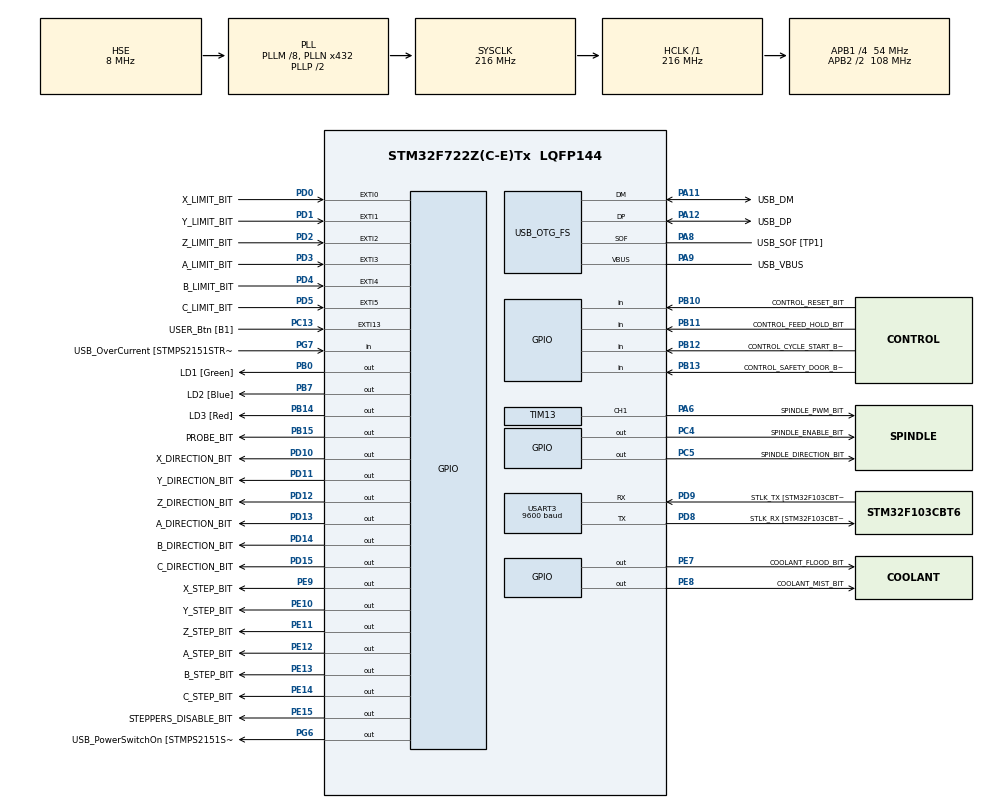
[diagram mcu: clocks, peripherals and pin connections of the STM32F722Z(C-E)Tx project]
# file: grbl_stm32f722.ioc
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Mcu.Family=STM32F7
Mcu.Name=STM32F722Z(C-E)Tx
Mcu.Package=LQFP144
NVIC.EXTI0_IRQn=true\:0\:0\:false\:false\:true\:true\:true
NVIC.EXTI15_10_IRQn=true\:0\:0\:false\:false\:true\:true\:true
NVIC.EXTI1_IRQn=true\:0\:0\:false\:false\:true\:true\:true
NVIC.EXTI2_IRQn=true\:0\:0\:false\:false\:true\:true\:true
NVIC.EXTI3_IRQn=true\:0\:0\:false\:false\:true\:true\:true
NVIC.EXTI4_IRQn=true\:0\:0\:false\:false\:true\:true\:true
NVIC.EXTI9_5_IRQn=true\:0\:0\:false\:false\:true\:true\:true
NVIC.PriorityGroup=NVIC_PRIORITYGROUP_4
NVIC.TIM6_DAC_IRQn=true\:0\:0\:false\:false\:true\:true\:true
NVIC.TIM7_IRQn=true\:0\:0\:false\:false\:true\:true\:true
NVIC.USART3_IRQn=true\:0\:0\:false\:false\:true\:true\:true
PA10.GPIO_Label=USB_ID
PA10.Signal=USB_OTG_FS_ID
PA11.GPIO_Label=USB_DM
PA11.Mode=Device_Only
PA11.Signal=USB_OTG_FS_DM
PA12.GPIO_Label=USB_DP
PA12.Mode=Device_Only
PA12.Signal=USB_OTG_FS_DP
PA13.GPIO_Label=TMS
PA13.Mode=Serial_Wire
PA13.Signal=SYS_JTMS-SWDIO
PA14.GPIO_Label=TCK
PA14.Mode=Serial_Wire
PA14.Signal=SYS_JTCK-SWCLK
PA6.GPIO_Label=SPINDLE_PWM_BIT
PA6.Signal=S_TIM13_CH1
PA8.GPIO_Label=USB_SOF [TP1]
PA8.Mode=Activate_SOF_FS
PA8.Signal=USB_OTG_FS_SOF
PA9.GPIO_Label=USB_VBUS
PA9.Mode=Activate_VBUS
PA9.Signal=USB_OTG_FS_VBUS
PB0.GPIO_Label=LD1 [Green]
PB0.Signal=GPIO_Output
PB10.GPIO_Label=CONTROL_RESET_BIT
PB10.GPIO_PuPd=GPIO_PULLUP
PB10.Signal=GPIO_Input
PB11.GPIO_Label=CONTROL_FEED_HOLD_BIT
PB11.GPIO_PuPd=GPIO_PULLUP
PB11.Signal=GPIO_Input
PB12.GPIO_Label=CONTROL_CYCLE_START_BIT
PB12.GPIO_PuPd=GPIO_PULLUP
PB12.Signal=GPIO_Input
PB13.GPIO_Label=CONTROL_SAFETY_DOOR_BIT
PB13.GPIO_PuPd=GPIO_PULLUP
PB13.Signal=GPIO_Input
PB14.GPIO_Label=LD3 [Red]
PB14.Signal=GPIO_Output
PB15.GPIO_Label=PROBE_BIT
PB15.Signal=GPIO_Output
PB3.GPIO_Label=SWO
PB3.Signal=SYS_JTDO-SWO
PB7.GPIO_Label=LD2 [Blue]
PB7.Signal=GPIO_Output
PC13.GPIO_Label=USER_Btn [B1]
PC13.Signal=GPXTI13
PC14-OSC32_IN.Mode=LSE-External-Oscillator
PC14-OSC32_IN.Signal=RCC_OSC32_IN
PC15-OSC32_OUT.Mode=LSE-External-Oscillator
PC15-OSC32_OUT.Signal=RCC_OSC32_OUT
PC4.GPIO_Label=SPINDLE_ENABLE_BIT
PC4.Signal=GPIO_Output
PC5.GPIO_Label=SPINDLE_DIRECTION_BIT
PC5.Signal=GPIO_Output
PD0.GPIO_Label=X_LIMIT_BIT
PD0.GPIO_PuPd=GPIO_PULLUP
PD0.Signal=GPXTI0
PD1.GPIO_Label=Y_LIMIT_BIT
PD1.GPIO_PuPd=GPIO_PULLUP
PD1.Signal=GPXTI1
PD10.GPIO_Label=X_DIRECTION_BIT
PD10.Signal=GPIO_Output
PD11.GPIO_Label=Y_DIRECTION_BIT
PD11.Signal=GPIO_Output
PD12.GPIO_Label=Z_DIRECTION_BIT
PD12.Signal=GPIO_Output
PD13.GPIO_Label=A_DIRECTION_BIT
PD13.Signal=GPIO_Output
PD14.GPIO_Label=B_DIRECTION_BIT
PD14.Signal=GPIO_Output
PD15.GPIO_Label=C_DIRECTION_BIT
PD15.Signal=GPIO_Output
PD2.GPIO_Label=Z_LIMIT_BIT
PD2.GPIO_PuPd=GPIO_PULLUP
PD2.Signal=GPXTI2
PD3.GPIO_Label=A_LIMIT_BIT
PD3.GPIO_PuPd=GPIO_PULLUP
PD3.Signal=GPXTI3
PD4.GPIO_Label=B_LIMIT_BIT
PD4.GPIO_PuPd=GPIO_PULLUP
PD4.Signal=GPXTI4
PD5.GPIO_Label=C_LIMIT_BIT
PD5.GPIO_PuPd=GPIO_PULLUP
PD5.Signal=GPXTI5
PD8.GPIO_Label=STLK_RX [STM32F103CBT6_PA3]
PD8.Mode=Asynchronous
PD8.Signal=USART3_TX
PD9.GPIO_Label=STLK_TX [STM32F103CBT6_PA2]
PD9.Mode=Asynchronous
PD9.Signal=USART3_RX
PE10.GPIO_Label=Y_STEP_BIT
PE10.Signal=GPIO_Output
PE11.GPIO_Label=Z_STEP_BIT
PE11.Signal=GPIO_Output
PE12.GPIO_Label=A_STEP_BIT
PE12.Signal=GPIO_Output
PE13.GPIO_Label=B_STEP_BIT
PE13.Signal=GPIO_Output
PE14.GPIO_Label=C_STEP_BIT
PE14.Signal=GPIO_Output
PE15.GPIO_Label=STEPPERS_DISABLE_BIT
PE15.Signal=GPIO_Output
PE7.GPIO_Label=COOLANT_FLOOD_BIT
PE7.Signal=GPIO_Output
PE8.GPIO_Label=COOLANT_MIST_BIT
PE8.Signal=GPIO_Output
PE9.GPIO_Label=X_STEP_BIT
PE9.Signal=GPIO_Output
PG6.GPIO_Label=USB_PowerSwitchOn [STMPS2151STR_EN]
PG6.Signal=GPIO_Output
PG7.GPIO_Label=USB_OverCurrent [STMPS2151STR_FAULT]
PG7.Signal=GPIO_Input
PH0-OSC_IN.GPIO_Label=MCO
PH0-OSC_IN.Mode=HSE-External-Clock-Source
PH0-OSC_IN.Signal=RCC_OSC_IN
PH1-OSC_OUT.Mode=HSE-External-Clock-Source
PH1-OSC_OUT.Signal=RCC_OSC_OUT
ProjectManager.HeapSize=0x200
ProjectManager.StackSize=0x400
ProjectManager.TargetToolchain=STM32CubeIDE
RCC.48MHZClocksFreq_Value=24000000
RCC.AHBFreq_Value=216000000
RCC.APB1CLKDivider=RCC_HCLK_DIV4
RCC.APB1Freq_Value=54000000
RCC.APB1TimFreq_Value=108000000
RCC.APB2CLKDivider=RCC_HCLK_DIV2
RCC.APB2Freq_Value=108000000
RCC.APB2TimFreq_Value=216000000
RCC.CortexFreq_Value=216000000
RCC.HCLKFreq_Value=216000000
RCC.HSE_VALUE=8000000
RCC.HSI_VALUE=16000000
RCC.PLLM=8
RCC.PLLMUL=RCC_PLL_MUL9
RCC.PLLN=432
RCC.PLLQ=9
RCC.PRESCALERUSB=RCC_USBCLKSOURCE_PLL_DIV1_5
RCC.SYSCLKFreq_VALUE=216000000
RCC.SYSCLKSource=RCC_SYSCLKSOURCE_PLLCLK
RCC.SYSCLKSourceVirtual=RCC_SYSCLKSOURCE_PLLCLK
RCC.USBFreq_Value=48000000
RCC.VCOOutputFreq_Value=432000000
SH.S_TIM13_CH1.0=TIM13_CH1,PWM Generation1 CH1
TIM13.Channel=TIM_CHANNEL_1
TIM6.Prescaler=216
TIM7.Prescaler=216
USART3.BaudRate=9600
USART3.VirtualMode-Asynchronous=VM_ASYNC
USB_OTG_FS.VirtualMode=Device_Only
VP_TIM13_VS_ClockSourceINT.Mode=Enable_Timer
VP_TIM6_VS_ClockSourceINT.Mode=Enable_Timer
VP_TIM7_VS_ClockSourceINT.Mode=Enable_Timer
board=NUCLEO-F722ZE

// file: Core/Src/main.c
/* USER CODE BEGIN Header */
/**
  ******************************************************************************
  * @file           : main.c
  * @brief          : Main program body
  ******************************************************************************
  * @attention
  *
  * <h2><center>&copy; Copyright (c) 2020 STMicroelectronics.
  * All rights reserved.</center></h2>
  *
  * This software component is licensed by ST under BSD 3-Clause license,
  * the "License"; You may not use this file except in compliance with the
  * License. You may obtain a copy of the License at:
  *                        opensource.org/licenses/BSD-3-Clause
  *
  ******************************************************************************
  */
/* USER CODE END Header */

#include "main.h"

/* USER CODE BEGIN Includes */
#include "stm32_hal_port.h"

/* USER CODE END Includes */

TIM_HandleTypeDef htim6;
TIM_HandleTypeDef htim7;
TIM_HandleTypeDef htim13;

UART_HandleTypeDef huart3;

PCD_HandleTypeDef hpcd_USB_OTG_FS;

void SystemClock_Config(void);
static void MX_GPIO_Init(void);
static void MX_USART3_UART_Init(void);
static void MX_USB_OTG_FS_PCD_Init(void);
static void MX_TIM13_Init(void);
static void MX_TIM6_Init(void);
static void MX_TIM7_Init(void);

int main(void)
{

  /* MCU Configuration--------------------------------------------------------*/

  /* Reset of all peripherals, Initializes the Flash interface and the Systick. */
  HAL_Init();

  /* Configure the system clock */
  SystemClock_Config();

  /* Initialize all configured peripherals */
  MX_GPIO_Init();
  MX_USART3_UART_Init();
  MX_USB_OTG_FS_PCD_Init();
  MX_TIM13_Init();
  MX_TIM6_Init();
  MX_TIM7_Init();
  /* USER CODE BEGIN 2 */
  grbl_start();
  /* USER CODE END 2 */

  /* Infinite loop */
  while (1)
  {

  }
}

void SystemClock_Config(void)
{
  RCC_OscInitTypeDef RCC_OscInitStruct = {0};
  RCC_ClkInitTypeDef RCC_ClkInitStruct = {0};
  RCC_PeriphCLKInitTypeDef PeriphClkInitStruct = {0};

  /** Configure LSE Drive Capability
  */
  HAL_PWR_EnableBkUpAccess();
  /** Configure the main internal regulator output voltage
  */
  __HAL_RCC_PWR_CLK_ENABLE();
  __HAL_PWR_VOLTAGESCALING_CONFIG(PWR_REGULATOR_VOLTAGE_SCALE1);
  /** Initializes the CPU, AHB and APB busses clocks
  */
  RCC_OscInitStruct.OscillatorType = RCC_OSCILLATORTYPE_HSE;
  RCC_OscInitStruct.HSEState = RCC_HSE_BYPASS;
  RCC_OscInitStruct.PLL.PLLState = RCC_PLL_ON;
  RCC_OscInitStruct.PLL.PLLSource = RCC_PLLSOURCE_HSE;
  RCC_OscInitStruct.PLL.PLLM = 8;
  RCC_OscInitStruct.PLL.PLLN = 432;
  RCC_OscInitStruct.PLL.PLLP = RCC_PLLP_DIV2;
  RCC_OscInitStruct.PLL.PLLQ = 9;
  if (HAL_RCC_OscConfig(&RCC_OscInitStruct) != HAL_OK)
  {
    Error_Handler();
  }
  /** Activate the Over-Drive mode
  */
  if (HAL_PWREx_EnableOverDrive() != HAL_OK)
  {
    Error_Handler();
  }
  /** Initializes the CPU, AHB and APB busses clocks
  */
  RCC_ClkInitStruct.ClockType = RCC_CLOCKTYPE_HCLK|RCC_CLOCKTYPE_SYSCLK
                              |RCC_CLOCKTYPE_PCLK1|RCC_CLOCKTYPE_PCLK2;
  RCC_ClkInitStruct.SYSCLKSource = RCC_SYSCLKSOURCE_PLLCLK;
  RCC_ClkInitStruct.AHBCLKDivider = RCC_SYSCLK_DIV1;
  RCC_ClkInitStruct.APB1CLKDivider = RCC_HCLK_DIV4;
  RCC_ClkInitStruct.APB2CLKDivider = RCC_HCLK_DIV2;

  if (HAL_RCC_ClockConfig(&RCC_ClkInitStruct, FLASH_LATENCY_7) != HAL_OK)
  {
    Error_Handler();
  }
  PeriphClkInitStruct.PeriphClockSelection = RCC_PERIPHCLK_USART3|RCC_PERIPHCLK_CLK48;
  PeriphClkInitStruct.Usart3ClockSelection = RCC_USART3CLKSOURCE_PCLK1;
  PeriphClkInitStruct.Clk48ClockSelection = RCC_CLK48SOURCE_PLL;
  if (HAL_RCCEx_PeriphCLKConfig(&PeriphClkInitStruct) != HAL_OK)
  {
    Error_Handler();
  }
}

static void MX_TIM6_Init(void)
{

  TIM_MasterConfigTypeDef sMasterConfig = {0};

  htim6.Instance = TIM6;
  htim6.Init.Prescaler = 216;
  htim6.Init.CounterMode = TIM_COUNTERMODE_UP;
  htim6.Init.Period = 0;
  htim6.Init.AutoReloadPreload = TIM_AUTORELOAD_PRELOAD_DISABLE;
  if (HAL_TIM_Base_Init(&htim6) != HAL_OK)
  {
    Error_Handler();
  }
  sMasterConfig.MasterOutputTrigger = TIM_TRGO_RESET;
  sMasterConfig.MasterSlaveMode = TIM_MASTERSLAVEMODE_DISABLE;
  if (HAL_TIMEx_MasterConfigSynchronization(&htim6, &sMasterConfig) != HAL_OK)
  {
    Error_Handler();
  }

}

static void MX_TIM7_Init(void)
{

  TIM_MasterConfigTypeDef sMasterConfig = {0};

  htim7.Instance = TIM7;
  htim7.Init.Prescaler = 216;
  htim7.Init.CounterMode = TIM_COUNTERMODE_UP;
  htim7.Init.Period = 0;
  htim7.Init.AutoReloadPreload = TIM_AUTORELOAD_PRELOAD_DISABLE;
  if (HAL_TIM_Base_Init(&htim7) != HAL_OK)
  {
    Error_Handler();
  }
  sMasterConfig.MasterOutputTrigger = TIM_TRGO_RESET;
  sMasterConfig.MasterSlaveMode = TIM_MASTERSLAVEMODE_DISABLE;
  if (HAL_TIMEx_MasterConfigSynchronization(&htim7, &sMasterConfig) != HAL_OK)
  {
    Error_Handler();
  }

}

static void MX_TIM13_Init(void)
{

  TIM_OC_InitTypeDef sConfigOC = {0};

  htim13.Instance = TIM13;
  htim13.Init.Prescaler = 0;
  htim13.Init.CounterMode = TIM_COUNTERMODE_UP;
  htim13.Init.Period = 0;
  htim13.Init.ClockDivision = TIM_CLOCKDIVISION_DIV1;
  htim13.Init.AutoReloadPreload = TIM_AUTORELOAD_PRELOAD_DISABLE;
  if (HAL_TIM_Base_Init(&htim13) != HAL_OK)
  {
    Error_Handler();
  }
  if (HAL_TIM_PWM_Init(&htim13) != HAL_OK)
  {
    Error_Handler();
  }
  sConfigOC.OCMode = TIM_OCMODE_PWM1;
  sConfigOC.Pulse = 0;
  sConfigOC.OCPolarity = TIM_OCPOLARITY_HIGH;
  sConfigOC.OCFastMode = TIM_OCFAST_DISABLE;
  if (HAL_TIM_PWM_ConfigChannel(&htim13, &sConfigOC, TIM_CHANNEL_1) != HAL_OK)
  {
    Error_Handler();
  }
  HAL_TIM_MspPostInit(&htim13);

}

static void MX_USART3_UART_Init(void)
{

  huart3.Instance = USART3;
  huart3.Init.BaudRate = 9600;
  huart3.Init.WordLength = UART_WORDLENGTH_8B;
  huart3.Init.StopBits = UART_STOPBITS_1;
  huart3.Init.Parity = UART_PARITY_NONE;
  huart3.Init.Mode = UART_MODE_TX_RX;
  huart3.Init.HwFlowCtl = UART_HWCONTROL_NONE;
  huart3.Init.OverSampling = UART_OVERSAMPLING_16;
  huart3.Init.OneBitSampling = UART_ONE_BIT_SAMPLE_DISABLE;
  huart3.AdvancedInit.AdvFeatureInit = UART_ADVFEATURE_NO_INIT;
  if (HAL_UART_Init(&huart3) != HAL_OK)
  {
    Error_Handler();
  }

}

static void MX_USB_OTG_FS_PCD_Init(void)
{

  hpcd_USB_OTG_FS.Instance = USB_OTG_FS;
  hpcd_USB_OTG_FS.Init.dev_endpoints = 6;
  hpcd_USB_OTG_FS.Init.dma_enable = DISABLE;
  hpcd_USB_OTG_FS.Init.phy_itface = PCD_PHY_EMBEDDED;
  hpcd_USB_OTG_FS.Init.Sof_enable = ENABLE;
  hpcd_USB_OTG_FS.Init.low_power_enable = DISABLE;
  hpcd_USB_OTG_FS.Init.lpm_enable = DISABLE;
  hpcd_USB_OTG_FS.Init.battery_charging_enable = ENABLE;
  hpcd_USB_OTG_FS.Init.vbus_sensing_enable = ENABLE;
  hpcd_USB_OTG_FS.Init.use_dedicated_ep1 = DISABLE;
  if (HAL_PCD_Init(&hpcd_USB_OTG_FS) != HAL_OK)
  {
    Error_Handler();
  }

}

static void MX_GPIO_Init(void)
{
  GPIO_InitTypeDef GPIO_InitStruct = {0};

  /* GPIO Ports Clock Enable */
  __HAL_RCC_GPIOC_CLK_ENABLE();
  __HAL_RCC_GPIOH_CLK_ENABLE();
  __HAL_RCC_GPIOA_CLK_ENABLE();
  __HAL_RCC_GPIOB_CLK_ENABLE();
  __HAL_RCC_GPIOE_CLK_ENABLE();
  __HAL_RCC_GPIOD_CLK_ENABLE();
  __HAL_RCC_GPIOG_CLK_ENABLE();

  /*Configure GPIO pin Output Level */
  HAL_GPIO_WritePin(GPIOC, SPINDLE_ENABLE_BIT_Pin|SPINDLE_DIRECTION_BIT_Pin, GPIO_PIN_RESET);

  /*Configure GPIO pin Output Level */
  HAL_GPIO_WritePin(GPIOB, LD1_Pin|LD3_Pin|PROBE_BIT_Pin|LD2_Pin, GPIO_PIN_RESET);

  /*Configure GPIO pin Output Level */
  HAL_GPIO_WritePin(GPIOE, COOLANT_FLOOD_BIT_Pin|COOLANT_MIST_BIT_Pin|X_STEP_BIT_Pin|Y_STEP_BIT_Pin
                          |Z_STEP_BIT_Pin|A_STEP_BIT_Pin|B_STEP_BIT_Pin|C_STEP_BIT_Pin
                          |STEPPERS_DISABLE_BIT_Pin, GPIO_PIN_RESET);

  /*Configure GPIO pin Output Level */
  HAL_GPIO_WritePin(GPIOD, X_DIRECTION_BIT_Pin|Y_DIRECTION_BIT_Pin|Z_DIRECTION_BIT_Pin|A_DIRECTION_BIT_Pin
                          |B_DIRECTION_BIT_Pin|C_DIRECTION_BIT_Pin, GPIO_PIN_RESET);

  /*Configure GPIO pin Output Level */
  HAL_GPIO_WritePin(USB_PowerSwitchOn_GPIO_Port, USB_PowerSwitchOn_Pin, GPIO_PIN_RESET);

  /*Configure GPIO pin : USER_Btn_Pin */
  GPIO_InitStruct.Pin = USER_Btn_Pin;
  GPIO_InitStruct.Mode = GPIO_MODE_IT_RISING;
  GPIO_InitStruct.Pull = GPIO_NOPULL;
  HAL_GPIO_Init(USER_Btn_GPIO_Port, &GPIO_InitStruct);

  /*Configure GPIO pins : SPINDLE_ENABLE_BIT_Pin SPINDLE_DIRECTION_BIT_Pin */
  GPIO_InitStruct.Pin = SPINDLE_ENABLE_BIT_Pin|SPINDLE_DIRECTION_BIT_Pin;
  GPIO_InitStruct.Mode = GPIO_MODE_OUTPUT_PP;
  GPIO_InitStruct.Pull = GPIO_NOPULL;
  GPIO_InitStruct.Speed = GPIO_SPEED_FREQ_LOW;
  HAL_GPIO_Init(GPIOC, &GPIO_InitStruct);

  /*Configure GPIO pins : LD1_Pin LD3_Pin PROBE_BIT_Pin LD2_Pin */
  GPIO_InitStruct.Pin = LD1_Pin|LD3_Pin|PROBE_BIT_Pin|LD2_Pin;
  GPIO_InitStruct.Mode = GPIO_MODE_OUTPUT_PP;
  GPIO_InitStruct.Pull = GPIO_NOPULL;
  GPIO_InitStruct.Speed = GPIO_SPEED_FREQ_LOW;
  HAL_GPIO_Init(GPIOB, &GPIO_InitStruct);

  /*Configure GPIO pins : COOLANT_FLOOD_BIT_Pin COOLANT_MIST_BIT_Pin X_STEP_BIT_Pin Y_STEP_BIT_Pin
                           Z_STEP_BIT_Pin A_STEP_BIT_Pin B_STEP_BIT_Pin C_STEP_BIT_Pin
                           STEPPERS_DISABLE_BIT_Pin */
  GPIO_InitStruct.Pin = COOLANT_FLOOD_BIT_Pin|COOLANT_MIST_BIT_Pin|X_STEP_BIT_Pin|Y_STEP_BIT_Pin
                          |Z_STEP_BIT_Pin|A_STEP_BIT_Pin|B_STEP_BIT_Pin|C_STEP_BIT_Pin
                          |STEPPERS_DISABLE_BIT_Pin;
  GPIO_InitStruct.Mode = GPIO_MODE_OUTPUT_PP;
  GPIO_InitStruct.Pull = GPIO_NOPULL;
  GPIO_InitStruct.Speed = GPIO_SPEED_FREQ_LOW;
  HAL_GPIO_Init(GPIOE, &GPIO_InitStruct);

  /*Configure GPIO pins : CONTROL_RESET_BIT_Pin CONTROL_FEED_HOLD_BIT_Pin CONTROL_CYCLE_START_BIT_Pin CONTROL_SAFETY_DOOR_BIT_Pin */
  GPIO_InitStruct.Pin = CONTROL_RESET_BIT_Pin|CONTROL_FEED_HOLD_BIT_Pin|CONTROL_CYCLE_START_BIT_Pin|CONTROL_SAFETY_DOOR_BIT_Pin;
  GPIO_InitStruct.Mode = GPIO_MODE_INPUT;
  GPIO_InitStruct.Pull = GPIO_PULLUP;
  HAL_GPIO_Init(GPIOB, &GPIO_InitStruct);

  /*Configure GPIO pins : X_DIRECTION_BIT_Pin Y_DIRECTION_BIT_Pin Z_DIRECTION_BIT_Pin A_DIRECTION_BIT_Pin
                           B_DIRECTION_BIT_Pin C_DIRECTION_BIT_Pin */
  GPIO_InitStruct.Pin = X_DIRECTION_BIT_Pin|Y_DIRECTION_BIT_Pin|Z_DIRECTION_BIT_Pin|A_DIRECTION_BIT_Pin
                          |B_DIRECTION_BIT_Pin|C_DIRECTION_BIT_Pin;
  GPIO_InitStruct.Mode = GPIO_MODE_OUTPUT_PP;
  GPIO_InitStruct.Pull = GPIO_NOPULL;
  GPIO_InitStruct.Speed = GPIO_SPEED_FREQ_LOW;
  HAL_GPIO_Init(GPIOD, &GPIO_InitStruct);

  /*Configure GPIO pin : USB_PowerSwitchOn_Pin */
  GPIO_InitStruct.Pin = USB_PowerSwitchOn_Pin;
  GPIO_InitStruct.Mode = GPIO_MODE_OUTPUT_PP;
  GPIO_InitStruct.Pull = GPIO_NOPULL;
  GPIO_InitStruct.Speed = GPIO_SPEED_FREQ_LOW;
  HAL_GPIO_Init(USB_PowerSwitchOn_GPIO_Port, &GPIO_InitStruct);

  /*Configure GPIO pin : USB_OverCurrent_Pin */
  GPIO_InitStruct.Pin = USB_OverCurrent_Pin;
  GPIO_InitStruct.Mode = GPIO_MODE_INPUT;
  GPIO_InitStruct.Pull = GPIO_NOPULL;
  HAL_GPIO_Init(USB_OverCurrent_GPIO_Port, &GPIO_InitStruct);

  /*Configure GPIO pins : X_LIMIT_BIT_Pin Y_LIMIT_BIT_Pin Z_LIMIT_BIT_Pin A_LIMIT_BIT_Pin
                           B_LIMIT_BIT_Pin C_LIMIT_BIT_Pin */
  GPIO_InitStruct.Pin = X_LIMIT_BIT_Pin|Y_LIMIT_BIT_Pin|Z_LIMIT_BIT_Pin|A_LIMIT_BIT_Pin
                          |B_LIMIT_BIT_Pin|C_LIMIT_BIT_Pin;
  GPIO_InitStruct.Mode = GPIO_MODE_IT_RISING;
  GPIO_InitStruct.Pull = GPIO_PULLUP;
  HAL_GPIO_Init(GPIOD, &GPIO_InitStruct);

  /* EXTI interrupt init*/
  HAL_NVIC_SetPriority(EXTI0_IRQn, 0, 0);
  HAL_NVIC_EnableIRQ(EXTI0_IRQn);

  HAL_NVIC_SetPriority(EXTI1_IRQn, 0, 0);
  HAL_NVIC_EnableIRQ(EXTI1_IRQn);

  HAL_NVIC_SetPriority(EXTI2_IRQn, 0, 0);
  HAL_NVIC_EnableIRQ(EXTI2_IRQn);

  HAL_NVIC_SetPriority(EXTI3_IRQn, 0, 0);
  HAL_NVIC_EnableIRQ(EXTI3_IRQn);

  HAL_NVIC_SetPriority(EXTI4_IRQn, 0, 0);
  HAL_NVIC_EnableIRQ(EXTI4_IRQn);

  HAL_NVIC_SetPriority(EXTI9_5_IRQn, 0, 0);
  HAL_NVIC_EnableIRQ(EXTI9_5_IRQn);

  HAL_NVIC_SetPriority(EXTI15_10_IRQn, 0, 0);
  HAL_NVIC_EnableIRQ(EXTI15_10_IRQn);

}

void Error_Handler(void)
{
}

/************************ (C) COPYRIGHT STMicroelectronics *****END OF FILE****/
